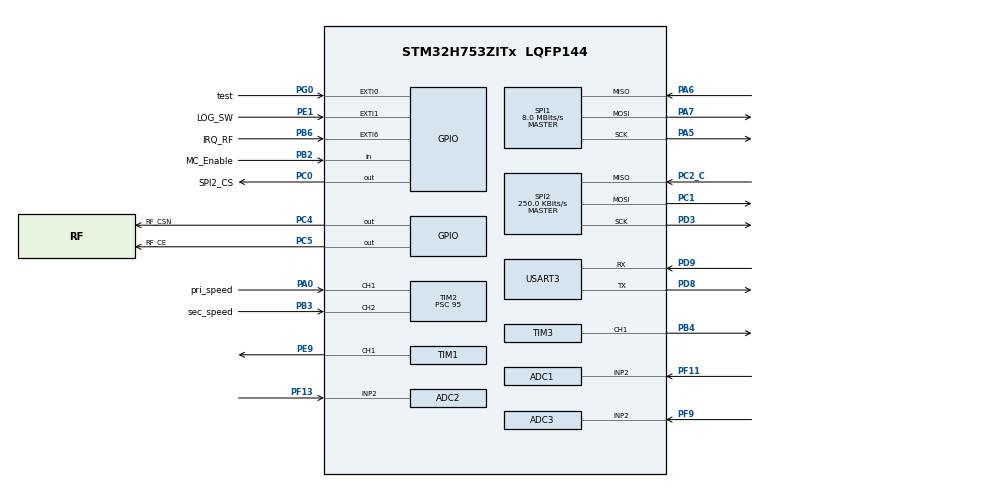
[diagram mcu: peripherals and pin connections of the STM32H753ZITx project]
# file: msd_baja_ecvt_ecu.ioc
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ADC1.Channel-0\#ChannelRegularConversion=ADC_CHANNEL_2
ADC1.ConversionDataManagement=ADC_CONVERSIONDATA_DMA_CIRCULAR
ADC1.ExternalTrigConv=ADC_EXTERNALTRIG_T6_TRGO
ADC1.NbrOfConversionFlag=1
ADC1.OffsetNumber-0\#ChannelRegularConversion=ADC_OFFSET_NONE
ADC1.OffsetSignedSaturation-0\#ChannelRegularConversion=DISABLE
ADC1.Rank-0\#ChannelRegularConversion=1
ADC1.Resolution=ADC_RESOLUTION_12B
ADC1.SamplingTime-0\#ChannelRegularConversion=ADC_SAMPLETIME_1CYCLE_5
ADC1.master=1
ADC2.Channel-0\#ChannelRegularConversion=ADC_CHANNEL_2
ADC2.ConversionDataManagement=ADC_CONVERSIONDATA_DMA_CIRCULAR
ADC2.ExternalTrigConv=ADC_EXTERNALTRIG_T6_TRGO
ADC2.NbrOfConversionFlag=1
ADC2.OffsetNumber-0\#ChannelRegularConversion=ADC_OFFSET_NONE
ADC2.OffsetSignedSaturation-0\#ChannelRegularConversion=DISABLE
ADC2.Rank-0\#ChannelRegularConversion=1
ADC2.Resolution=ADC_RESOLUTION_12B
ADC2.SamplingTime-0\#ChannelRegularConversion=ADC_SAMPLETIME_1CYCLE_5
ADC3.Channel-0\#ChannelRegularConversion=ADC_CHANNEL_2
ADC3.ConversionDataManagement=ADC_CONVERSIONDATA_DMA_CIRCULAR
ADC3.ExternalTrigConv=ADC_EXTERNALTRIG_T6_TRGO
ADC3.NbrOfConversionFlag=1
ADC3.OffsetNumber-0\#ChannelRegularConversion=ADC_OFFSET_NONE
ADC3.OffsetSignedSaturation-0\#ChannelRegularConversion=DISABLE
ADC3.Rank-0\#ChannelRegularConversion=1
ADC3.Resolution=ADC_RESOLUTION_12B
ADC3.SamplingTime-0\#ChannelRegularConversion=ADC_SAMPLETIME_1CYCLE_5
Bdma.ADC3.0.Direction=DMA_PERIPH_TO_MEMORY
Bdma.ADC3.0.EventEnable=DISABLE
Bdma.ADC3.0.Instance=BDMA_Channel0
Bdma.ADC3.0.MemDataAlignment=DMA_MDATAALIGN_HALFWORD
Bdma.ADC3.0.MemInc=DMA_MINC_ENABLE
Bdma.ADC3.0.Mode=DMA_CIRCULAR
Bdma.ADC3.0.PeriphDataAlignment=DMA_PDATAALIGN_HALFWORD
Bdma.ADC3.0.PeriphInc=DMA_PINC_DISABLE
Bdma.ADC3.0.Polarity=HAL_DMAMUX_REQ_GEN_RISING
Bdma.ADC3.0.Priority=DMA_PRIORITY_LOW
Bdma.ADC3.0.RequestNumber=1
Bdma.ADC3.0.SignalID=NONE
Bdma.ADC3.0.SyncEnable=DISABLE
Bdma.ADC3.0.SyncPolarity=HAL_DMAMUX_SYNC_NO_EVENT
Bdma.ADC3.0.SyncRequestNumber=1
Bdma.ADC3.0.SyncSignalID=NONE
Bdma.Request0=ADC3
Bdma.RequestsNb=1
CORTEX_M7.CPU_DCache=Disabled
CORTEX_M7.CPU_ICache=Disabled
CORTEX_M7.MPU_Control=__NULL
CORTEX_M7.default_mode_Activation=1
Dma.ADC1.0.Direction=DMA_PERIPH_TO_MEMORY
Dma.ADC1.0.EventEnable=DISABLE
Dma.ADC1.0.FIFOMode=DMA_FIFOMODE_DISABLE
Dma.ADC1.0.Instance=DMA1_Stream0
Dma.ADC1.0.MemDataAlignment=DMA_MDATAALIGN_HALFWORD
Dma.ADC1.0.MemInc=DMA_MINC_ENABLE
Dma.ADC1.0.Mode=DMA_CIRCULAR
Dma.ADC1.0.PeriphDataAlignment=DMA_PDATAALIGN_HALFWORD
Dma.ADC1.0.PeriphInc=DMA_PINC_DISABLE
Dma.ADC1.0.Polarity=HAL_DMAMUX_REQ_GEN_RISING
Dma.ADC1.0.Priority=DMA_PRIORITY_LOW
Dma.ADC1.0.RequestNumber=1
Dma.ADC1.0.SignalID=NONE
Dma.ADC1.0.SyncEnable=DISABLE
Dma.ADC1.0.SyncPolarity=HAL_DMAMUX_SYNC_NO_EVENT
Dma.ADC1.0.SyncRequestNumber=1
Dma.ADC1.0.SyncSignalID=NONE
Dma.ADC2.1.Direction=DMA_PERIPH_TO_MEMORY
Dma.ADC2.1.EventEnable=DISABLE
Dma.ADC2.1.FIFOMode=DMA_FIFOMODE_DISABLE
Dma.ADC2.1.Instance=DMA1_Stream1
Dma.ADC2.1.MemDataAlignment=DMA_MDATAALIGN_HALFWORD
Dma.ADC2.1.MemInc=DMA_MINC_ENABLE
Dma.ADC2.1.Mode=DMA_CIRCULAR
Dma.ADC2.1.PeriphDataAlignment=DMA_PDATAALIGN_HALFWORD
Dma.ADC2.1.PeriphInc=DMA_PINC_DISABLE
Dma.ADC2.1.Polarity=HAL_DMAMUX_REQ_GEN_RISING
Dma.ADC2.1.Priority=DMA_PRIORITY_LOW
Dma.ADC2.1.RequestNumber=1
Dma.ADC2.1.SignalID=NONE
Dma.ADC2.1.SyncEnable=DISABLE
Dma.ADC2.1.SyncPolarity=HAL_DMAMUX_SYNC_NO_EVENT
Dma.ADC2.1.SyncRequestNumber=1
Dma.ADC2.1.SyncSignalID=NONE
Dma.Request0=ADC1
Dma.Request1=ADC2
Dma.Request2=TIM2_CH2
Dma.Request3=TIM2_CH1
Dma.TIM2_CH1.3.Direction=DMA_PERIPH_TO_MEMORY
Dma.TIM2_CH1.3.EventEnable=DISABLE
Dma.TIM2_CH1.3.FIFOMode=DMA_FIFOMODE_DISABLE
Dma.TIM2_CH1.3.Instance=DMA1_Stream2
Dma.TIM2_CH1.3.MemDataAlignment=DMA_MDATAALIGN_WORD
Dma.TIM2_CH1.3.MemInc=DMA_MINC_ENABLE
Dma.TIM2_CH1.3.Mode=DMA_CIRCULAR
Dma.TIM2_CH1.3.PeriphDataAlignment=DMA_PDATAALIGN_WORD
Dma.TIM2_CH1.3.PeriphInc=DMA_PINC_DISABLE
Dma.TIM2_CH1.3.Polarity=HAL_DMAMUX_REQ_GEN_RISING
Dma.TIM2_CH1.3.Priority=DMA_PRIORITY_LOW
Dma.TIM2_CH1.3.RequestNumber=1
Dma.TIM2_CH1.3.SignalID=NONE
Dma.TIM2_CH1.3.SyncEnable=DISABLE
Dma.TIM2_CH1.3.SyncPolarity=HAL_DMAMUX_SYNC_NO_EVENT
Dma.TIM2_CH1.3.SyncRequestNumber=1
Dma.TIM2_CH1.3.SyncSignalID=NONE
Dma.TIM2_CH2.2.Direction=DMA_PERIPH_TO_MEMORY
Dma.TIM2_CH2.2.EventEnable=DISABLE
Dma.TIM2_CH2.2.FIFOMode=DMA_FIFOMODE_DISABLE
Dma.TIM2_CH2.2.Instance=DMA1_Stream3
Dma.TIM2_CH2.2.MemDataAlignment=DMA_MDATAALIGN_WORD
Dma.TIM2_CH2.2.MemInc=DMA_MINC_ENABLE
Dma.TIM2_CH2.2.Mode=DMA_CIRCULAR
Dma.TIM2_CH2.2.PeriphDataAlignment=DMA_PDATAALIGN_WORD
Dma.TIM2_CH2.2.PeriphInc=DMA_PINC_DISABLE
Dma.TIM2_CH2.2.Polarity=HAL_DMAMUX_REQ_GEN_RISING
Dma.TIM2_CH2.2.Priority=DMA_PRIORITY_LOW
Dma.TIM2_CH2.2.RequestNumber=1
Dma.TIM2_CH2.2.SignalID=NONE
Dma.TIM2_CH2.2.SyncEnable=DISABLE
Dma.TIM2_CH2.2.SyncPolarity=HAL_DMAMUX_SYNC_NO_EVENT
Dma.TIM2_CH2.2.SyncRequestNumber=1
Dma.TIM2_CH2.2.SyncSignalID=NONE
FREERTOS.Queues01=helix_angle_queue,16,float,0,Dynamic,NULL,NULL;throttle_angle_queue,16,float,0,Dynamic,NULL,NULL;pri_rpm_queue,16,float,0,Dynamic,NULL,NULL;sec_rpm_queue,16,float,0,Dynamic,NULL,NULL;pidconfig_queue,4,PIDConfig,0,Dynamic,NULL,NULL;RFCommandQueue,16,16,1,Dynamic,NULL,NULL;sensor_data_mc_q,4,sensor_data_t,0,Dynamic,NULL,NULL;sensor_data_debug_q,4,sensor_data_t,0,Dynamic,NULL,NULL;sensor_data_log_q,60,sensor_data_t,0,Dynamic,NULL,NULL
FREERTOS.Tasks01=defaultTask,24,128,StartDefaultTask,Default,NULL,Dynamic,NULL,NULL;Sensor_Reading,38,1028,Start_Sensor_Reading,Default,NULL,Dynamic,NULL,NULL;Motor_Control,39,1028,Start_Motor_Control,Default,NULL,Dynamic,NULL,NULL;Debug_Disp,8,256,Start_Debug_Disp,Default,NULL,Dynamic,NULL,NULL;ReceiveRF,29,512,receiveRFCommand,Default,NULL,Dynamic,NULL,NULL;processRF,20,1028,processRFCommand,Default,NULL,Dynamic,NULL,NULL;loggingTask,27,512,logData,Default,NULL,Dynamic,NULL,NULL
FREERTOS.configTOTAL_HEAP_SIZE=28000
FREERTOS.configUSE_NEWLIB_REENTRANT=1
Mcu.Family=STM32H7
Mcu.Name=STM32H753ZITx
Mcu.Package=LQFP144
NUCLEO-H753ZI.BUTTON=1
NUCLEO-H753ZI.LD1=true
NUCLEO-H753ZI.LD2=true
NUCLEO-H753ZI.LD3=true
NUCLEO-H753ZI.VCP=false
NVIC.BDMA_Channel0_IRQn=true\:5\:0\:false\:false\:true\:true\:false\:true\:true
NVIC.DMA1_Stream0_IRQn=true\:5\:0\:false\:false\:true\:true\:false\:true\:true
NVIC.DMA1_Stream1_IRQn=true\:5\:0\:false\:false\:true\:true\:false\:true\:true
NVIC.DMA1_Stream2_IRQn=true\:5\:0\:false\:false\:true\:true\:false\:true\:true
NVIC.DMA1_Stream3_IRQn=true\:5\:0\:false\:false\:true\:true\:false\:true\:true
NVIC.EXTI0_IRQn=true\:5\:0\:false\:false\:true\:true\:true\:true\:true
NVIC.EXTI15_10_IRQn=true\:5\:0\:false\:false\:true\:true\:false\:true\:true
NVIC.EXTI1_IRQn=true\:5\:0\:false\:false\:true\:true\:true\:true\:true
NVIC.EXTI9_5_IRQn=true\:5\:0\:false\:false\:true\:true\:true\:true\:true
NVIC.PriorityGroup=NVIC_PRIORITYGROUP_4
NVIC.SPI1_IRQn=true\:5\:0\:false\:false\:true\:true\:true\:true\:true
NVIC.TIM17_IRQn=true\:15\:0\:false\:false\:true\:false\:false\:true\:true
NVIC.TimeBase=TIM17_IRQn
NVIC.TimeBaseIP=TIM17
NVIC.USART3_IRQn=true\:5\:0\:false\:false\:true\:true\:true\:true\:true
PA0.GPIO_Label=pri_speed
PA0.GPIO_ModeDefaultPP=GPIO_MODE_AF_OD
PA0.GPIO_PuPd=GPIO_NOPULL
PA0.GPIO_Speed=GPIO_SPEED_FREQ_VERY_HIGH
PA0.Signal=S_TIM2_CH1_ETR
PA5.Mode=Full_Duplex_Master
PA5.Signal=SPI1_SCK
PA6.Mode=Full_Duplex_Master
PA6.Signal=SPI1_MISO
PA7.Mode=Full_Duplex_Master
PA7.Signal=SPI1_MOSI
PB2.GPIO_Label=MC_Enable
PB2.GPIO_PuPd=GPIO_PULLUP
PB2.Signal=GPIO_Input
PB3\ (JTDO/TRACESWO).GPIO_Label=sec_speed
PB3\ (JTDO/TRACESWO).GPIO_ModeDefaultPP=GPIO_MODE_AF_OD
PB3\ (JTDO/TRACESWO).GPIO_PuPd=GPIO_NOPULL
PB3\ (JTDO/TRACESWO).GPIO_Speed=GPIO_SPEED_FREQ_VERY_HIGH
PB3\ (JTDO/TRACESWO).Signal=S_TIM2_CH2
PB4\ (NJTRST).Signal=S_TIM3_CH1
PB6.GPIO_Label=IRQ_RF
PB6.GPIO_ModeDefaultEXTI=GPIO_MODE_IT_FALLING
PB6.GPIO_PuPd=GPIO_PULLUP
PB6.Signal=GPXTI6
PC0.GPIO_Label=SPI2_CS
PC0.GPIO_PuPd=GPIO_PULLUP
PC0.GPIO_Speed=GPIO_SPEED_FREQ_MEDIUM
PC0.PinState=GPIO_PIN_SET
PC0.Signal=GPIO_Output
PC1.GPIO_PuPd=GPIO_NOPULL
PC1.GPIO_Speed=GPIO_SPEED_FREQ_VERY_HIGH
PC1.Mode=Full_Duplex_Master
PC1.Signal=SPI2_MOSI
PC14-OSC32_IN\ (OSC32_IN).Signal=RCC_OSC32_IN
PC15-OSC32_OUT\ (OSC32_OUT).Signal=RCC_OSC32_OUT
PC2_C.GPIO_PuPd=GPIO_PULLUP
PC2_C.GPIO_Speed=GPIO_SPEED_FREQ_VERY_HIGH
PC2_C.Mode=Full_Duplex_Master
PC2_C.Signal=SPI2_MISO
PC4.GPIO_Label=RF_CSN
PC4.GPIO_Speed=GPIO_SPEED_FREQ_HIGH
PC4.Signal=GPIO_Output
PC5.GPIO_Label=RF_CE
PC5.GPIO_Speed=GPIO_SPEED_FREQ_HIGH
PC5.Signal=GPIO_Output
PD3.GPIO_PuPd=GPIO_NOPULL
PD3.GPIO_Speed=GPIO_SPEED_FREQ_VERY_HIGH
PD3.Mode=Full_Duplex_Master
PD3.Signal=SPI2_SCK
PD8.Mode=Asynchronous
PD8.Signal=USART3_TX
PD9.Mode=Asynchronous
PD9.Signal=USART3_RX
PE1.GPIO_Label=LOG_SW
PE1.GPIO_ModeDefaultEXTI=GPIO_MODE_IT_RISING_FALLING
PE1.GPIO_PuPd=GPIO_PULLUP
PE1.Signal=GPXTI1
PE9.Signal=S_TIM1_CH1
PF11.Mode=IN2-Single-Ended
PF11.Signal=ADC1_INP2
PF13.Mode=IN2-Single-Ended
PF13.Signal=ADC2_INP2
PF9.Mode=IN2-Single-Ended
PF9.Signal=ADC3_INP2
PG0.GPIO_Label=test
PG0.GPIO_PuPd=GPIO_PULLUP
PG0.Signal=GPXTI0
PH0-OSC_IN\ (PH0).Signal=RCC_OSC_IN
PH1-OSC_OUT\ (PH1).Signal=RCC_OSC_OUT
ProjectManager.HeapSize=0x200
ProjectManager.StackSize=0x400
ProjectManager.TargetToolchain=STM32CubeIDE
RCC.ADCFreq_Value=80000000
RCC.APB1Freq_Value=48000000
RCC.APB2Freq_Value=96000000
RCC.APB3Freq_Value=96000000
RCC.APB4Freq_Value=96000000
RCC.CortexFreq_Value=96000000
RCC.D2PPRE1=RCC_APB1_DIV2
RCC.DIVM1=4
RCC.DIVM2=4
RCC.DIVN1=12
RCC.DIVN2=10
RCC.DIVQ1=3
RCC.HCLKFreq_Value=96000000
RCC.HSE_VALUE=8000000
RCC.PLL2FRACN=0
RCC.PLL3FRACN=0
RCC.PLLFRACN=0
RCC.PWR_Regulator_Voltage_Scale=PWR_REGULATOR_VOLTAGE_SCALE2
RCC.SYSCLKFreq_VALUE=96000000
RCC.SYSCLKSource=RCC_SYSCLKSOURCE_PLLCLK
RCC.USBFreq_Value=64000000
SH.S_TIM1_CH1.0=TIM1_CH1,PWM Generation1 CH1
SH.S_TIM2_CH1_ETR.0=TIM2_CH1,Input_Capture1_from_TI1
SH.S_TIM2_CH2.0=TIM2_CH2,Input_Capture2_from_TI2
SH.S_TIM3_CH1.0=TIM3_CH1,PWM Generation1 CH1
SPI1.BaudRatePrescaler=SPI_BAUDRATEPRESCALER_8
SPI1.CalculateBaudRate=8.0 MBits/s
SPI1.DataSize=SPI_DATASIZE_8BIT
SPI1.Direction=SPI_DIRECTION_2LINES
SPI1.Mode=SPI_MODE_MASTER
SPI1.VirtualType=VM_MASTER
SPI2.BaudRatePrescaler=SPI_BAUDRATEPRESCALER_256
SPI2.CalculateBaudRate=250.0 KBits/s
SPI2.DataSize=SPI_DATASIZE_8BIT
SPI2.Direction=SPI_DIRECTION_2LINES
SPI2.Mode=SPI_MODE_MASTER
SPI2.VirtualType=VM_MASTER
TIM1.Channel-PWM\ Generation1\ CH1=TIM_CHANNEL_1
TIM1.ClockDivision=TIM_CLOCKDIVISION_DIV1
TIM1.Period=39999
TIM1.Prescaler=11
TIM2.Channel-Input_Capture1_from_TI1=TIM_CHANNEL_1
TIM2.Channel-Input_Capture2_from_TI2=TIM_CHANNEL_2
TIM2.ICPolarity_CH2=TIM_INPUTCHANNELPOLARITY_FALLING
TIM2.Prescaler=95
TIM3.Channel-PWM\ Generation1\ CH1=TIM_CHANNEL_1
TIM3.ClockDivision=TIM_CLOCKDIVISION_DIV4
TIM3.Period=39999
TIM3.Prescaler=11
TIM5.Prescaler=95
TIM6.Period=47999
TIM6.Prescaler=2
TIM6.TIM_MasterOutputTrigger=TIM_TRGO_UPDATE
USART3.VirtualMode-Asynchronous=VM_ASYNC
VP_FATFS_VS_Generic.Mode=User_defined
VP_FREERTOS_VS_CMSIS_V2.Mode=CMSIS_V2
VP_MEMORYMAP_VS_MEMORYMAP.Mode=CurAppReg
VP_NUCLEO-H753ZI_VS_BSP_COMMON.Mode=COMMON
VP_SYS_VS_tim17.Mode=TIM17
VP_TIM15_VS_ClockSourceINT.Mode=Internal
VP_TIM5_VS_ClockSourceINT.Mode=Internal
VP_TIM6_VS_ClockSourceINT.Mode=Enable_Timer
board=NUCLEO-H753ZI

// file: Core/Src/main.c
/* USER CODE BEGIN Header */
/**
  ******************************************************************************
  * @file           : main.c
  * @brief          : Main program body
  ******************************************************************************
  * @attention
  *
  * Copyright (c) 2026 STMicroelectronics.
  * All rights reserved.
  *
  * This software is licensed under terms that can be found in the LICENSE file
  * in the root directory of this software component.
  * If no LICENSE file comes with this software, it is provided AS-IS.
  *
  ******************************************************************************
  */
/* USER CODE END Header */
#include "main.h"
#include "cmsis_os.h"
#include "adc.h"
#include "bdma.h"
#include "dma.h"
#include "fatfs.h"
#include "spi.h"
#include "tim.h"
#include "usart.h"
#include "gpio.h"

/* USER CODE BEGIN Includes */
#include <string.h>
#include <stdio.h>
#include <stdlib.h>
#include "Controller_P7.h"
#include "NRF24.h"
#include "NRF24_reg_addresses.h"
/* USER CODE END Includes */

/* USER CODE BEGIN PD */
#define PLD_SIZE 16
#define DEBUG 1
/* USER CODE END PD */

void SystemClock_Config(void);
void PeriphCommonClock_Config(void);
void MX_FREERTOS_Init(void);
/* USER CODE BEGIN PFP */
int _read(int file, char *ptr, int len);
int __io_getchar(void);
// PID Functions
int  INIT_PID              (void);
int CHANGE_PID             (char* code, float value);
void PRINT_PID   		   (void);
// SD Card Functions
int  START_LOG			   (void);
void STOP_LOG			   (void);
int  LOG_DATA_POINT		   (int time, int engine_rpm, int box_rpm);
int  FIND_LOG_LINES		   (void);
// RF Function
int  TRANSMIT_LOG		   (void);
// Timer Functions
void TIM6_SetPeriod_us     (uint32_t us);
//E1
/* USER CODE END PFP */

/* USER CODE BEGIN 0 */
// some variables for FatFs
FATFS FatFs;
FIL fil_PID, fil_LOG; // TODO: Create two log files, one for log and one for PID so they don't interfere
FRESULT fres;
BYTE SDreadBuf[64];
char msg[128];
volatile int log_rate = 100; // Default logging rate in us
// RF Variables
volatile uint8_t nrf_irq_flag = 0;
uint8_t addr_ecvt[5] = {0x20,0x21,0x32,0x43,0x54};
uint8_t addr_gui[5]  = {0x10,0x21,0x32,0x43,0x54};
char complete_msg[10] = "COMPLETE";
typedef struct __attribute__((packed)) {
    uint32_t time;
    uint16_t engine_rpm;
    uint16_t box_rpm;
} CompactLogEntry;
// LOG variables
volatile bool isLogging = 0;
volatile uint8_t logSwitchflg = 0;
volatile uint8_t record_log_flag = 0;
volatile uint8_t uart_command_flag = 0;
char line_buffer[64];
uint8_t rx_uart3_buffer[64];
int rx_uart3_index = 0;
int log_index = 0;
uint8_t rx_byte;

/* USER CODE END 0 */

int main(void)
{

  /* MCU Configuration--------------------------------------------------------*/

  /* Reset of all peripherals, Initializes the Flash interface and the Systick. */
  HAL_Init();

  /* Configure the system clock */
  SystemClock_Config();

  /* Configure the peripherals common clocks */
  PeriphCommonClock_Config();

  /* USER CODE BEGIN SysInit */
  HAL_SYSCFG_AnalogSwitchConfig(SYSCFG_SWITCH_PC2, SYSCFG_SWITCH_PC2_CLOSE);

  /* USER CODE END SysInit */

  /* Initialize all configured peripherals */
  MX_GPIO_Init();
  MX_DMA_Init();
  MX_BDMA_Init();
  MX_ADC1_Init();
  MX_TIM6_Init();
  MX_ADC2_Init();
  MX_TIM2_Init();
  MX_TIM3_Init();
  MX_TIM1_Init();
  MX_SPI1_Init();
  MX_FATFS_Init();
  MX_ADC3_Init();
  MX_TIM5_Init();
  MX_TIM15_Init();
  MX_SPI2_Init();
  MX_USART3_UART_Init();
  /* USER CODE BEGIN 2 */
  printf("\x1B[?25l\x1B[2J\x1B[H");

  // NRF24 init
  csn_high();
  nrf24_init();
  nrf24_tx_pwr(_0dbm);
  nrf24_data_rate(_2mbps);
  nrf24_set_channel(7);
  nrf24_set_crc(en_crc, _1byte);
  nrf24_pipe_pld_size(0, PLD_SIZE);
  nrf24_auto_ack_all(enable);     // Enable ACKs for all pipes
  nrf24_auto_retr_delay(5);       // Set delay (5 = 1500us). Critical for reliable ACKs.
  nrf24_auto_retr_limit(15);      // Try up to 15 times before giving up
  nrf24_mode_rx(addr_ecvt);

  HAL_UART_Receive_IT(&huart3, &rx_byte, 1);
  HAL_TIM_Base_Start(&htim5);
  /* USER CODE END 2 */

  /* Init scheduler */
  osKernelInitialize();  /* Call init function for freertos objects (in cmsis_os2.c) */
  MX_FREERTOS_Init();

  /* Initialize leds */
  BSP_LED_Init(LED_GREEN);
  BSP_LED_Init(LED_BLUE);
  BSP_LED_Init(LED_RED);

  /* Initialize USER push-button, will be used to trigger an interrupt each time it's pressed.*/
  BSP_PB_Init(BUTTON_USER, BUTTON_MODE_EXTI);

  /* Start scheduler */
  osKernelStart();

  /* We should never get here as control is now taken by the scheduler */

  /* Infinite loop */
  while (1)
  {

  }
}

void SystemClock_Config(void)
{
  RCC_OscInitTypeDef RCC_OscInitStruct = {0};
  RCC_ClkInitTypeDef RCC_ClkInitStruct = {0};

  /** Supply configuration update enable
  */
  HAL_PWREx_ConfigSupply(PWR_LDO_SUPPLY);

  /** Configure the main internal regulator output voltage
  */
  __HAL_PWR_VOLTAGESCALING_CONFIG(PWR_REGULATOR_VOLTAGE_SCALE2);

  while(!__HAL_PWR_GET_FLAG(PWR_FLAG_VOSRDY)) {}

  /** Initializes the RCC Oscillators according to the specified parameters
  * in the RCC_OscInitTypeDef structure.
  */
  RCC_OscInitStruct.OscillatorType = RCC_OSCILLATORTYPE_HSI;
  RCC_OscInitStruct.HSIState = RCC_HSI_DIV1;
  RCC_OscInitStruct.HSICalibrationValue = RCC_HSICALIBRATION_DEFAULT;
  RCC_OscInitStruct.PLL.PLLState = RCC_PLL_ON;
  RCC_OscInitStruct.PLL.PLLSource = RCC_PLLSOURCE_HSI;
  RCC_OscInitStruct.PLL.PLLM = 4;
  RCC_OscInitStruct.PLL.PLLN = 12;
  RCC_OscInitStruct.PLL.PLLP = 2;
  RCC_OscInitStruct.PLL.PLLQ = 3;
  RCC_OscInitStruct.PLL.PLLR = 2;
  RCC_OscInitStruct.PLL.PLLRGE = RCC_PLL1VCIRANGE_3;
  RCC_OscInitStruct.PLL.PLLVCOSEL = RCC_PLL1VCOWIDE;
  RCC_OscInitStruct.PLL.PLLFRACN = 0;
  if (HAL_RCC_OscConfig(&RCC_OscInitStruct) != HAL_OK)
  {
    Error_Handler();
  }

  /** Initializes the CPU, AHB and APB buses clocks
  */
  RCC_ClkInitStruct.ClockType = RCC_CLOCKTYPE_HCLK|RCC_CLOCKTYPE_SYSCLK
                              |RCC_CLOCKTYPE_PCLK1|RCC_CLOCKTYPE_PCLK2
                              |RCC_CLOCKTYPE_D3PCLK1|RCC_CLOCKTYPE_D1PCLK1;
  RCC_ClkInitStruct.SYSCLKSource = RCC_SYSCLKSOURCE_PLLCLK;
  RCC_ClkInitStruct.SYSCLKDivider = RCC_SYSCLK_DIV1;
  RCC_ClkInitStruct.AHBCLKDivider = RCC_HCLK_DIV1;
  RCC_ClkInitStruct.APB3CLKDivider = RCC_APB3_DIV1;
  RCC_ClkInitStruct.APB1CLKDivider = RCC_APB1_DIV2;
  RCC_ClkInitStruct.APB2CLKDivider = RCC_APB2_DIV1;
  RCC_ClkInitStruct.APB4CLKDivider = RCC_APB4_DIV1;

  if (HAL_RCC_ClockConfig(&RCC_ClkInitStruct, FLASH_LATENCY_1) != HAL_OK)
  {
    Error_Handler();
  }
}

void PeriphCommonClock_Config(void)
{
  RCC_PeriphCLKInitTypeDef PeriphClkInitStruct = {0};

  /** Initializes the peripherals clock
  */
  PeriphClkInitStruct.PeriphClockSelection = RCC_PERIPHCLK_ADC;
  PeriphClkInitStruct.PLL2.PLL2M = 4;
  PeriphClkInitStruct.PLL2.PLL2N = 10;
  PeriphClkInitStruct.PLL2.PLL2P = 2;
  PeriphClkInitStruct.PLL2.PLL2Q = 2;
  PeriphClkInitStruct.PLL2.PLL2R = 2;
  PeriphClkInitStruct.PLL2.PLL2RGE = RCC_PLL2VCIRANGE_3;
  PeriphClkInitStruct.PLL2.PLL2VCOSEL = RCC_PLL2VCOMEDIUM;
  PeriphClkInitStruct.PLL2.PLL2FRACN = 0;
  PeriphClkInitStruct.AdcClockSelection = RCC_ADCCLKSOURCE_PLL2;
  if (HAL_RCCEx_PeriphCLKConfig(&PeriphClkInitStruct) != HAL_OK)
  {
    Error_Handler();
  }
}

/* USER CODE BEGIN 4 */
int _read(int file, char *ptr, int len)
{
    //HAL_UART_Receive(&hcom_uart[COM1], (uint8_t *)ptr, 1, HAL_MAX_DELAY);
    return 1;
}

int __io_getchar(void)
{
    uint8_t ch;
    //HAL_UART_Receive(&hcom_uart[COM1], &ch, 1, HAL_MAX_DELAY);
    return ch;
}

void HAL_GPIO_EXTI_Callback(uint16_t GPIO_Pin)
{
    if(GPIO_Pin == IRQ_RF_Pin)
    {
        nrf_irq_flag = 1;
    }

    if(GPIO_Pin == LOG_SW_Pin){
    	logSwitchflg = 1;
    }
}

void HAL_UART_RxCpltCallback(UART_HandleTypeDef *huart)
{
    if (huart->Instance == USART3)
    {
        // 1. DO SOMETHING with the data (e.g., save it to a buffer)
    	rx_uart3_buffer[rx_uart3_index++] = rx_byte;

    	if(rx_byte == '\n' || rx_byte == '\r'){
    		uart_command_flag = 1;
    		rx_uart3_index = 0;
    	}
        // 2. RE-ENABLE the interrupt
        HAL_UART_Receive_IT(&huart3, &rx_byte, 1);
    }
}

void HAL_UART_ErrorCallback(UART_HandleTypeDef *huart)
{
    if (huart->Instance == USART3)
    {
    	// Force the UART state back to "Ready"
    	huart3.RxState = HAL_UART_STATE_READY;
    	huart3.Lock = HAL_UNLOCKED;

    	// Clear all hardware error flags
    	__HAL_UART_CLEAR_OREFLAG(&huart3);

    	// Try to start again
    	HAL_UART_Receive_IT(&huart3, &rx_byte, 1);
    }
}

// Reads the PID.txt saved PID values and assigns them to the PID data structure (Controller_P7_P)
// Returns 0 if the file was unable to be opened and 1 if the PID value assignments were successful
int INIT_PID(){
	int temp_int;
	float temp_float;
	fres = f_mount(&FatFs, "", 1);
    if (fres != FR_OK) {
	  return 0;
    }

	// Open file
	fres = f_open(&fil_PID, "PID.txt", FA_READ);
    if (fres != FR_OK) {
    	return 0;
    }

	// 1. Read Log Rate (Line 1)
	if (f_gets((TCHAR*)SDreadBuf, sizeof(SDreadBuf), &fil_PID)) {
		// "Log Rate %lf" skips the text and reads the double
		sscanf((TCHAR*)SDreadBuf, "Log Rate %d", &log_rate);
	} else {
		return 0;
	}

	// 2. Read the 4 PID sets (4 lines each)
	for (int i = 0; i < 16; i++) {
	    // Read P line
	    if (f_gets((TCHAR*)SDreadBuf, sizeof(SDreadBuf), &fil_PID)) {
	        if(i == 3 || i == 11){ // All values except RPM Low and High set points are floats
	        	sscanf((TCHAR*)SDreadBuf, " %*s %d", &temp_int);
	        } else{
	        	sscanf((TCHAR*)SDreadBuf, " %*s %f", &temp_float);
	        }
	        // Set correct variable in control scheme

	        switch(i){
				case 0: // P1
					Controller_P7_P.Prop_RPM_Low = temp_float;
					break;
				case 1: // I1
					Controller_P7_P.Int_RPM_Low = temp_float;
					break;
				case 2: // D1
					Controller_P7_P.Der_RPM_Low = temp_float;
					break;
				case 3: // Low RPM SP
					Controller_P7_P.Omega_Low = temp_int;
					break;
				case 4: // P2
					Controller_P7_P.Prop_GR_Low = temp_float;
					break;
				case 5: // I2
					Controller_P7_P.Int_GR_Low = temp_float;
					break;
				case 6: // D2
					Controller_P7_P.Der_GR_Low = temp_float;
					break;
				case 7: // Low Gear SP
					Controller_P7_P.Phi_max = temp_float;
					break;
				case 8: // P3
					Controller_P7_P.Prop_RPM_High = temp_float;
					break;
				case 9: // I3
					Controller_P7_P.Int_RPM_High = temp_float;
					break;
				case 10: // D3
					Controller_P7_P.Der_RPM_High = temp_float;
					break;
				case 11: // High RPM SP
					Controller_P7_P.Omega_High = temp_int;
					break;
				case 12: // P4
					Controller_P7_P.Prop_GR_High = temp_float;
					break;
				case 13: // I4
					Controller_P7_P.Int_GR_High = temp_float;
					break;
				case 14: // D4
					Controller_P7_P.Der_GR_High = temp_float;
					break;
				case 15: // High Gear SP
					Controller_P7_P.Phi_min = temp_float;
					break;
	        }
	    } else {
	       return 0;
	    }
	}

    // Close file
    f_close(&fil_PID);

    // De-mount drive
//    f_mount(NULL, "", 0);

    return 1;

}

// Changes the PID values in the PID structure and overwrites the value in PID.txt
// Takes in the code in string (Ex. P1, I4, SP2) and the value to change it to
// Returns 0 if the file writing was unsuccessful and 1 if it was successfully written to PID.txt
int CHANGE_PID(char* code, float value){

	if (strncmp(code, "P1", 2) == 0) {
	    Controller_P7_P.Prop_RPM_Low = (real_T) value;
	} else if (strncmp(code, "I1", 2) == 0) {
	    Controller_P7_P.Int_RPM_Low = (real_T) value;
	} else if (strncmp(code, "D1", 2) == 0) {
	    Controller_P7_P.Der_RPM_Low = (real_T) value;
	} else if (strncmp(code, "SP1", 3) == 0) {
	    Controller_P7_P.Omega_Low = (real_T) value;
	} else if (strncmp(code, "P2", 2) == 0) {
	    Controller_P7_P.Prop_GR_Low = (real_T) value;
	} else if (strncmp(code, "I2", 2) == 0) {
	    Controller_P7_P.Int_GR_Low = (real_T) value;
	} else if (strncmp(code, "D2", 2) == 0) {
	    Controller_P7_P.Der_GR_Low = (real_T) value;
	} else if (strncmp(code, "SP2", 3) == 0) {
	    Controller_P7_P.Phi_max = (real_T) value;
	} else if (strncmp(code, "P3", 2) == 0) {
	    Controller_P7_P.Prop_RPM_High = (real_T) value;
	} else if (strncmp(code, "I3", 2) == 0) {
	    Controller_P7_P.Int_RPM_High = (real_T) value;
	} else if (strncmp(code, "D3", 2) == 0) {
	    Controller_P7_P.Der_RPM_High = (real_T) value;
	} else if (strncmp(code, "SP3", 3) == 0) {
	    Controller_P7_P.Omega_High = (real_T) value;
	} else if (strncmp(code, "P4", 2) == 0) {
	    Controller_P7_P.Prop_GR_High = (real_T) value;
	} else if (strncmp(code, "I4", 2) == 0) {
	    Controller_P7_P.Int_GR_High = (real_T) value;
	} else if (strncmp(code, "D4", 2) == 0) {
	    Controller_P7_P.Der_GR_High = (real_T) value;
	} else if (strncmp(code, "SP4", 3) == 0) {
	    Controller_P7_P.Phi_min = (real_T) value;
	} else if (strncmp(code, "LOG", 3) == 0){
		// Do nothing
	} else {
		 return 0;
	}

	// Mount drive
	fres = f_mount(&FatFs, "", 1);
	if (fres != FR_OK) {
	    return 0;
	}

	// Open file
	fres = f_open(&fil_PID, "PID.txt", FA_WRITE | FA_OPEN_ALWAYS | FA_CREATE_ALWAYS);
	if (fres != FR_OK) {
	    return 0;
	}

	char line_buffer[64];

	// Write logging rate
	sprintf(line_buffer, "Log Rate %d\r\n", (int)log_rate);
	f_puts(line_buffer, &fil_PID);
	// P1
	sprintf(line_buffer, "P1 %0.3f\r\n", (double)Controller_P7_P.Prop_RPM_Low);
	f_puts(line_buffer, &fil_PID);
	// I1
	sprintf(line_buffer, "I1 %0.3f\r\n", (double)Controller_P7_P.Int_RPM_Low);
	f_puts(line_buffer, &fil_PID);
	// D1
	sprintf(line_buffer, "D1 %0.3f\r\n", (double)Controller_P7_P.Der_RPM_Low);
	f_puts(line_buffer, &fil_PID);
	// SP1
	sprintf(line_buffer, "SP1 %d\r\n", (int)Controller_P7_P.Omega_Low);
	f_puts(line_buffer, &fil_PID);
	// P2
	sprintf(line_buffer, "P2 %0.3f\r\n", (double)Controller_P7_P.Prop_GR_Low);
	f_puts(line_buffer, &fil_PID);
	// I2
	sprintf(line_buffer, "I2 %0.3f\r\n", (double)Controller_P7_P.Int_GR_Low);
	f_puts(line_buffer, &fil_PID);
	// D2
	sprintf(line_buffer, "D2 %0.3f\r\n", (double)Controller_P7_P.Der_GR_Low);
	f_puts(line_buffer, &fil_PID);
	// SP2
	sprintf(line_buffer, "SP2 %0.3f\r\n", (double)Controller_P7_P.Phi_max);
	f_puts(line_buffer, &fil_PID);
	// P3
	sprintf(line_buffer, "P3 %0.3f\r\n", (double)Controller_P7_P.Prop_RPM_High);
	f_puts(line_buffer, &fil_PID);
	// I3
	sprintf(line_buffer, "I3 %0.3f\r\n", (double)Controller_P7_P.Int_RPM_High);
	f_puts(line_buffer, &fil_PID);
	// D3
	sprintf(line_buffer, "D3 %0.3f\r\n", (double)Controller_P7_P.Der_RPM_High);
	f_puts(line_buffer, &fil_PID);
	// SP3
	sprintf(line_buffer, "SP3 %d\r\n", (int)Controller_P7_P.Omega_High);
	f_puts(line_buffer, &fil_PID);
	// P4
	sprintf(line_buffer, "P4 %0.3f\r\n", (double)Controller_P7_P.Prop_GR_High);
	f_puts(line_buffer, &fil_PID);
	// I4
	sprintf(line_buffer, "I4 %0.3f\r\n", (double)Controller_P7_P.Int_GR_High);
	f_puts(line_buffer, &fil_PID);
	// D4
	sprintf(line_buffer, "D4 %0.3f\r\n", (double)Controller_P7_P.Der_GR_High);
	f_puts(line_buffer, &fil_PID);
	// SP4
	sprintf(line_buffer, "SP4 %0.3f\r\n", (double)Controller_P7_P.Phi_min);
	f_puts(line_buffer, &fil_PID);

	// Close file
	f_close(&fil_PID);
	// De-mount drive
//	f_mount(NULL, "", 0);
	return 1;
}

// Creates "LOG.txt" which overwrites (clears) the previously created log file
// Opens the global file variable
// Returns 1 if successful and 0 if unsuccessful
// Creates "LOG.txt" which overwrites (clears) the previously created log file
// Opens the global file variable
// Returns 1 if successful and 0 if unsuccessful
int START_LOG(){
    FILINFO fno;
    int max_logs = 100;
    char log_file_str[32];

    // Check for what log files exist
    for(int i = 0; i < max_logs; i++){
        snprintf(log_file_str, sizeof(log_file_str), "LOG%d.txt", i);
        fres = f_stat(log_file_str, &fno);
        if(fres == FR_NO_FILE){
            log_index = i;
            break;
        }
        // Maximum log file limit reached
        if(i == max_logs-1){
            return 0;
        }
    }

    // Clear file
    fres = f_open(&fil_LOG, log_file_str, FA_WRITE | FA_OPEN_ALWAYS | FA_CREATE_ALWAYS);
    if (fres != FR_OK) {
        return 0;
    }

    // Log Current PID values at the start of the log
    sprintf(msg, "P1:%.2f I1:%.2f D1:%.2f SP1:%d\r\n",
            (double)Controller_P7_P.Prop_RPM_Low, (double)Controller_P7_P.Int_RPM_Low, (double)Controller_P7_P.Der_RPM_Low, (int)Controller_P7_P.Omega_Low);
    if (f_puts(msg, &fil_LOG) < 0) {
        return 0;
    }
    sprintf(msg, "P2:%.2f I2:%.2f D2:%.2f SP2:%.2f\r\n",
            (double)Controller_P7_P.Prop_GR_Low, (double)Controller_P7_P.Int_GR_Low, (double)Controller_P7_P.Der_GR_Low, (double)Controller_P7_P.Phi_max);
    if (f_puts(msg, &fil_LOG) < 0) {
        return 0;
    }
    sprintf(msg, "P3:%.2f I3:%.2f D3:%.2f SP3:%d\r\n",
            (double)Controller_P7_P.Prop_RPM_High, (double)Controller_P7_P.Int_RPM_High, (double)Controller_P7_P.Der_RPM_High, (int)Controller_P7_P.Omega_High);
    if (f_puts(msg, &fil_LOG) < 0) {
        return 0;
    }
    sprintf(msg, "P4:%.2f I4:%.2f D4:%.2f SP4:%.2f\r\n",
            (double)Controller_P7_P.Prop_GR_High, (double)Controller_P7_P.Int_GR_High, (double)Controller_P7_P.Der_GR_High, (double)Controller_P7_P.Phi_min);
    if (f_puts(msg, &fil_LOG) < 0) {
        return 0;
    }

    return 1;
}

// Closes the global log file (LOG.txt)
void STOP_LOG(){
	// Close file
	f_close(&fil_LOG);
	// De-mount drive
//	f_mount(NULL, "", 0);
}

// Finds the amount of logged data points in LOG.txt (# of lines)
// Returns a positive integer if successful and -1 if not
int FIND_LOG_LINES(){
	int lines_count = 0;

	// Mount drive
	fres = f_mount(&FatFs, "", 1);
	if (fres != FR_OK) {
		return -1;
	}
	// Open file
	fres = f_open(&fil_LOG, "LOG.txt", FA_READ);
	if (fres != FR_OK) {
		return -1;
	}

	while(f_gets((TCHAR*)SDreadBuf, sizeof(SDreadBuf), &fil_LOG)){
		lines_count++;
	}
	if (lines_count > 0) {
	    lines_count++; // account for last line without newline
	}
	// Close file
	f_close(&fil_LOG);
	// De-mount drive
	f_mount(NULL, "", 0);

	return lines_count;
}

void TRANSMIT_LOG_USB(){
    int log_transmitted_index = 0;
    char log_file_str[32];
    char log_line[64];
    // Open log files starting from index 0
    snprintf(log_file_str, sizeof(log_file_str), "LOG%d.txt", log_transmitted_index);

    // While the file LOGx.txt exists
    while(f_open(&fil_LOG, log_file_str, FA_READ) == FR_OK){
        // Indicate to the GUI the start of a log file by printing the log file's name
        printf(log_file_str);
        printf("\r\n");
        // Loop through the log points if the log file exists
        while(f_gets(log_line, sizeof(log_line), &fil_LOG)){
            // Send the log line over USART
            printf(log_line);
        }
        // Move on to the next log file
        log_transmitted_index++;
        snprintf(log_file_str, sizeof(log_file_str), "LOG%d.txt", log_transmitted_index);
    }
    printf("COMPLETE\r\n");
}

// Logs a data point (one line) into LOG.txt (Assumes LOG.txt is open)
// Takes in the data to be logged (time, engine_rpm, and box_rpm)
// Returns 1 if the data point was siccessfully logged and 0 if the f_puts fails
int LOG_DATA_POINT(int time, int engine_rpm, int box_rpm){

    if(f_lseek(&fil_LOG, f_size(&fil_LOG)) != FR_OK){
        return 0;
    }

    // Write logging rate
    sprintf(line_buffer, "%d %d %d\n", time, engine_rpm, box_rpm);
    if (f_puts(line_buffer, &fil_LOG) < 0) {
        return 0;
    }

    return 1;
}

int TRANSMIT_LOG(){
	CompactLogEntry entry;
	if(isLogging){ // Only send when not currently logging
		return 0;
	}
	// Switch to transmit
	nrf24_mode_tx(addr_gui);

	// Get the number of lines in the log file
	int log_lines = FIND_LOG_LINES();
	char log_lines_str[32] = "";
	snprintf(log_lines_str, sizeof(log_lines_str), "%d", log_lines);

	HAL_Delay(100);
	fres = f_mount(&FatFs, "", 1);
	if (fres != FR_OK) {
	  return 0;
	  }
	HAL_Delay(100);
	// Open file
	fres = f_open(&fil_LOG, "LOG.txt", FA_READ);
	if (fres != FR_OK) {
	  return 0;
	}

	// Transmit complete message (Ensure that the NRF24 has switched modes)
	nrf_irq_flag = 0;
	uint8_t result;
	for(int i = 0; i< 50; i++){
	   result = nrf24_transmit_wait((uint8_t*)log_lines_str, strlen(log_lines_str));
	   HAL_Delay(10);
//	   BSP_LED_On(LED_RED);
	   if(result == 0){
//		   BSP_LED_Off(LED_RED);
		   break;
	   }
	}
	nrf_irq_flag = 0;
	char line[64];
	uint8_t status;
	// Begin log file transmission
	if (result == 0) {
		while (f_gets(line, sizeof(line), &fil_LOG)) {
			// Parse text file into our binary struct
			if(sscanf(line, "%lu %hu %hu", &entry.time, &entry.engine_rpm, &entry.box_rpm) >= 3) {
//				BSP_LED_Toggle(LED_RED);
				// Send binary struct
//				while(1){
//					status = nrf24_transmit_wait((uint8_t*)&entry, sizeof(entry));
//					DEBUG_RF();
//					if (status == 0) {
//						break;
//					}
//				}
//
//				if (status != 0) {
//					nrf24_flush_tx(); // Clear the failed packet from buffer
//				}
			}
		}

	} else {
		nrf24_flush_rx();
		// Switch back to receive
		nrf24_mode_rx(addr_ecvt);
		// Close file
		f_close(&fil_LOG);
		// De-mount drive
		f_mount(NULL, "", 0);
		return 0; // Error in intial transmission (Timeout)

	}

	for(int i = 0; i< 50; i++){
		result = nrf24_transmit_wait((uint8_t*)complete_msg, strlen(complete_msg));
		if(result == 0){
			break;
		}
	}

	nrf24_flush_rx();
	// Switch back to receive
	nrf24_mode_rx(addr_ecvt);

	// Close file
	f_close(&fil_LOG);

	// De-mount drive
	f_mount(NULL, "", 0);

	if(result == 0){
		return 1;
	} else {
		return 0;
	}

}

/**
 * @brief  Sets TIM6 interrupt period in microseconds
 * @param  us: Target period in microseconds (e.g., 1000 for 1ms)
 * @retval None
 */
void TIM6_SetPeriod_us(uint32_t us) {
    // 1. Get the PCLK1 frequency
    uint32_t pclk1 = HAL_RCC_GetPCLK1Freq();

    // 2. Determine the actual Timer Clock (H7 doubles it if APB1 divider != 1)
    uint32_t tim_clk;
    if ((RCC->D2CFGR & RCC_D2CFGR_D2PPRE1) == 0) {
        tim_clk = pclk1;
    } else {
        tim_clk = pclk1 * 2;
    }

    // 3. Get the current Prescaler from the register
    uint32_t current_psc = TIM6->PSC + 1;

    // 4. Calculate ARR for microseconds
    // Logic: ARR = (Clock * Seconds) / PSC
    // Since 'us' is microseconds, we divide the denominator by 1,000,000
    uint64_t arr_value = ((uint64_t)tim_clk * us) / (1000000ULL * current_psc);

    // 5. Apply limits for 16-bit Timer
    if (arr_value > 65536) {
        arr_value = 65536;
    } else if (arr_value < 1) {
        arr_value = 1;
    }

    // 6. Update the register
    __HAL_TIM_SET_AUTORELOAD(&htim6, (uint32_t)(arr_value - 1));
}

void PRINT_PID(){
	// 1. Verify Log Rate
	sprintf(msg, "Log Rate Parsed: %d\r\n", log_rate);
	printf(msg);

	// 2. Verify PID Array Values
	sprintf(msg, "P1:%.3f I1:%.3f D1:%.3f SP1:%d\r\n",
			(double)Controller_P7_P.Prop_RPM_Low, (double)Controller_P7_P.Int_RPM_Low, (double)Controller_P7_P.Der_RPM_Low, (int)Controller_P7_P.Omega_Low);
	printf(msg);
	sprintf(msg, "P2:%.3f I2:%.3f D2:%.3f SP2:%.3f\r\n",
			(double)Controller_P7_P.Prop_GR_Low, (double)Controller_P7_P.Int_GR_Low, (double)Controller_P7_P.Der_GR_Low, (double)Controller_P7_P.Phi_max);
	printf(msg);
	sprintf(msg, "P3:%.3f I3:%.3f D3:%.3f SP3:%d\r\n",
			(double)Controller_P7_P.Prop_RPM_High, (double)Controller_P7_P.Int_RPM_High, (double)Controller_P7_P.Der_RPM_High, (int)Controller_P7_P.Omega_High);
	printf(msg);
	sprintf(msg, "P4:%.3f I4:%.3f D4:%.3f SP4:%.3f\r\n",
			(double)Controller_P7_P.Prop_GR_High, (double)Controller_P7_P.Int_GR_High, (double)Controller_P7_P.Der_GR_High, (double)Controller_P7_P.Phi_min);
	printf(msg);
}
/* USER CODE END 4 */

void HAL_TIM_PeriodElapsedCallback(TIM_HandleTypeDef *htim)
{
  if (htim->Instance == TIM17)
  {
    HAL_IncTick();
  }
  /* USER CODE BEGIN Callback 1 */
  if (htim->Instance == TIM6)
  {
//	  if (isLogging)
//	  {
		record_log_flag = 1;
//	  }
  }
  /* USER CODE END Callback 1 */
}

void Error_Handler(void)
{
  __disable_irq();
  while (1)
  {
  }
}

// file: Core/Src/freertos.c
/* USER CODE BEGIN Header */
/**
  ******************************************************************************
  * File Name          : freertos.c
  * Description        : Code for freertos applications
  ******************************************************************************
  * @attention
  *
  * Copyright (c) 2026 STMicroelectronics.
  * All rights reserved.
  *
  * This software is licensed under terms that can be found in the LICENSE file
  * in the root directory of this software component.
  * If no LICENSE file comes with this software, it is provided AS-IS.
  *
  ******************************************************************************
  */
/* USER CODE END Header */

#include "FreeRTOS.h"
#include "task.h"
#include "main.h"
#include "cmsis_os.h"

/* USER CODE BEGIN Includes */
#include "print_debug.h"
#include <stdio.h>
#include <stddef.h>
#include "adc.h"
#include "tim.h"
#include "motor_control.h"
#include "sensor_filter.h"
#include "Controller_P7.h"
#include "sensor_conversion.h"
#include "main.h"
#include "NRF24.h"
#include "NRF24_reg_addresses.h"

/* USER CODE END Includes */

/* USER CODE BEGIN PD */
#define HELIX_ANGLE_BUF_LEN 1
#define THROTTLE_ANGLE_BUF_LEN 1
#define MOTOR_CURR_BUF_LEN 1
#define PRIM_RPM_BUF_LEN 2
#define SEC_RPM_BUF_LEN 2

#define NEUTRAL 11999
#define MAX_FORWARD	15999
#define MAX_REVERSE 7999
#define PWM_RANGE 8000

#define MOTOR_CONTROL 2

#define PLD_SIZE 16

#define DEBUG 1

/* USER CODE END PD */

/* USER CODE BEGIN Variables */
uint16_t helix_angle_buf[HELIX_ANGLE_BUF_LEN];
uint16_t throttle_angle_buf[THROTTLE_ANGLE_BUF_LEN];

uint16_t motor_curr_buf[MOTOR_CURR_BUF_LEN] __attribute__((section(".sram4_section")));
uint32_t prim_rpm_buf[PRIM_RPM_BUF_LEN];
uint32_t sec_rpm_buf[SEC_RPM_BUF_LEN];

//  uint16_t speed = NEUTRAL_SPEED;
//  uint16_t curr_position = 0;
//  uint16_t pos_setpoint = 0;
//  uint16_t helix_angle = 0;
extern DMA_HandleTypeDef hdma_tim2_ch1;
extern DMA_HandleTypeDef hdma_tim2_ch2;

// RF Variables
extern uint8_t nrf_irq_flag;
extern int log_rate;
uint8_t data_Rx[PLD_SIZE*5];

// LOG Variables
extern uint8_t record_log_flag;
extern bool isLogging;
extern uint8_t logSwitchflg;
extern uint8_t uart_command_flag;
extern uint8_t rx_uart3_buffer[64];

extern UART_HandleTypeDef huart3;

#if DEBUG == 1
uint32_t sensor_task_loop_time = 0;
uint32_t mc_task_loop_time = 0;
uint32_t log_task_loop_time = 0;
uint32_t rfrec_task_loop_time = 0;
uint32_t proc_rf_task_loop_time = 0;
#endif
/* USER CODE END Variables */
/* Definitions for defaultTask */
osThreadId_t defaultTaskHandle;
const osThreadAttr_t defaultTask_attributes = {
  .name = "defaultTask",
  .stack_size = 128 * 4,
  .priority = (osPriority_t) osPriorityNormal,
};
/* Definitions for Sensor_Reading */
osThreadId_t Sensor_ReadingHandle;
const osThreadAttr_t Sensor_Reading_attributes = {
  .name = "Sensor_Reading",
  .stack_size = 1028 * 4,
  .priority = (osPriority_t) osPriorityAboveNormal6,
};
/* Definitions for Motor_Control */
osThreadId_t Motor_ControlHandle;
const osThreadAttr_t Motor_Control_attributes = {
  .name = "Motor_Control",
  .stack_size = 1028 * 4,
  .priority = (osPriority_t) osPriorityAboveNormal7,
};
/* Definitions for Debug_Disp */
osThreadId_t Debug_DispHandle;
const osThreadAttr_t Debug_Disp_attributes = {
  .name = "Debug_Disp",
  .stack_size = 256 * 4,
  .priority = (osPriority_t) osPriorityLow,
};
/* Definitions for ReceiveRF */
osThreadId_t ReceiveRFHandle;
const osThreadAttr_t ReceiveRF_attributes = {
  .name = "ReceiveRF",
  .stack_size = 512 * 4,
  .priority = (osPriority_t) osPriorityNormal5,
};
/* Definitions for processRF */
osThreadId_t processRFHandle;
const osThreadAttr_t processRF_attributes = {
  .name = "processRF",
  .stack_size = 1028 * 4,
  .priority = (osPriority_t) osPriorityBelowNormal4,
};
/* Definitions for loggingTask */
osThreadId_t loggingTaskHandle;
const osThreadAttr_t loggingTask_attributes = {
  .name = "loggingTask",
  .stack_size = 512 * 4,
  .priority = (osPriority_t) osPriorityNormal3,
};
/* Definitions for helix_angle_queue */
osMessageQueueId_t helix_angle_queueHandle;
const osMessageQueueAttr_t helix_angle_queue_attributes = {
  .name = "helix_angle_queue"
};
/* Definitions for throttle_angle_queue */
osMessageQueueId_t throttle_angle_queueHandle;
const osMessageQueueAttr_t throttle_angle_queue_attributes = {
  .name = "throttle_angle_queue"
};
/* Definitions for pri_rpm_queue */
osMessageQueueId_t pri_rpm_queueHandle;
const osMessageQueueAttr_t pri_rpm_queue_attributes = {
  .name = "pri_rpm_queue"
};
/* Definitions for sec_rpm_queue */
osMessageQueueId_t sec_rpm_queueHandle;
const osMessageQueueAttr_t sec_rpm_queue_attributes = {
  .name = "sec_rpm_queue"
};
/* Definitions for pidconfig_queue */
osMessageQueueId_t pidconfig_queueHandle;
const osMessageQueueAttr_t pidconfig_queue_attributes = {
  .name = "pidconfig_queue"
};
/* Definitions for RFCommandQueue */
osMessageQueueId_t RFCommandQueueHandle;
const osMessageQueueAttr_t RFCommandQueue_attributes = {
  .name = "RFCommandQueue"
};
/* Definitions for sensor_data_mc_q */
osMessageQueueId_t sensor_data_mc_qHandle;
const osMessageQueueAttr_t sensor_data_mc_q_attributes = {
  .name = "sensor_data_mc_q"
};
/* Definitions for sensor_data_debug_q */
osMessageQueueId_t sensor_data_debug_qHandle;
const osMessageQueueAttr_t sensor_data_debug_q_attributes = {
  .name = "sensor_data_debug_q"
};
/* Definitions for sensor_data_log_q */
osMessageQueueId_t sensor_data_log_qHandle;
const osMessageQueueAttr_t sensor_data_log_q_attributes = {
  .name = "sensor_data_log_q"
};

void StartDefaultTask(void *argument);
void Start_Sensor_Reading(void *argument);
void Start_Motor_Control(void *argument);
void Start_Debug_Disp(void *argument);
void receiveRFCommand(void *argument);
void processRFCommand(void *argument);
void logData(void *argument);

void MX_FREERTOS_Init(void); /* (MISRA C 2004 rule 8.1) */

void MX_FREERTOS_Init(void) {

  /* Create the queue(s) */
  /* creation of helix_angle_queue */
  helix_angle_queueHandle = osMessageQueueNew (16, sizeof(float), &helix_angle_queue_attributes);

  /* creation of throttle_angle_queue */
  throttle_angle_queueHandle = osMessageQueueNew (16, sizeof(float), &throttle_angle_queue_attributes);

  /* creation of pri_rpm_queue */
  pri_rpm_queueHandle = osMessageQueueNew (16, sizeof(float), &pri_rpm_queue_attributes);

  /* creation of sec_rpm_queue */
  sec_rpm_queueHandle = osMessageQueueNew (16, sizeof(float), &sec_rpm_queue_attributes);

  /* creation of pidconfig_queue */
  pidconfig_queueHandle = osMessageQueueNew (4, sizeof(PIDConfig), &pidconfig_queue_attributes);

  /* creation of RFCommandQueue */
  RFCommandQueueHandle = osMessageQueueNew (16, 16, &RFCommandQueue_attributes);

  /* creation of sensor_data_mc_q */
  sensor_data_mc_qHandle = osMessageQueueNew (4, sizeof(sensor_data_t), &sensor_data_mc_q_attributes);

  /* creation of sensor_data_debug_q */
  sensor_data_debug_qHandle = osMessageQueueNew (4, sizeof(sensor_data_t), &sensor_data_debug_q_attributes);

  /* creation of sensor_data_log_q */
  sensor_data_log_qHandle = osMessageQueueNew (60, sizeof(sensor_data_t), &sensor_data_log_q_attributes);

  /* Create the thread(s) */
  /* creation of defaultTask */
  defaultTaskHandle = osThreadNew(StartDefaultTask, NULL, &defaultTask_attributes);

  /* creation of Sensor_Reading */
  Sensor_ReadingHandle = osThreadNew(Start_Sensor_Reading, NULL, &Sensor_Reading_attributes);

  /* creation of Motor_Control */
  Motor_ControlHandle = osThreadNew(Start_Motor_Control, NULL, &Motor_Control_attributes);

  /* creation of Debug_Disp */
  Debug_DispHandle = osThreadNew(Start_Debug_Disp, NULL, &Debug_Disp_attributes);

  /* creation of ReceiveRF */
  ReceiveRFHandle = osThreadNew(receiveRFCommand, NULL, &ReceiveRF_attributes);

  /* creation of processRF */
  processRFHandle = osThreadNew(processRFCommand, NULL, &processRF_attributes);

  /* creation of loggingTask */
  loggingTaskHandle = osThreadNew(logData, NULL, &loggingTask_attributes);

}

void StartDefaultTask(void *argument)
{
  /* USER CODE BEGIN StartDefaultTask */
  /* Infinite loop */
  for(;;)
  {
    osDelay(1000);
  }
  /* USER CODE END StartDefaultTask */
}

/* USER CODE BEGIN Header_Start_Sensor_Reading */
/**
* @brief Function implementing the Sensor_Reading thread.
* 		 This function takes in all sensor values from DMA
* 		 converts it to the required units,
* 		 then sends it to other threads for use
* @param argument: Not used
* @retval None
*/
/* USER CODE END Header_Start_Sensor_Reading */
void Start_Sensor_Reading(void *argument)
{
  /* USER CODE BEGIN Start_Sensor_Reading */
  /* Infinite loop */
	float helix_angle = 0;
	uint8_t helix_angle_prio = 0;
	float throttle_angle = 0;
	uint8_t throttle_angle_prio = 0;
	uint32_t prim_rpm_uint32 = 0;
	uint8_t prim_rpm_prio = 0;
	uint32_t sec_rpm_uint32 = 0;
	uint8_t sec_rpm_prio = 0;
	const uint32_t TIMEOUT = 0;
	SPEED_FIFO prim_speed_fifo = {0};
	uint32_t curr_prim_rpm_tic = 0;
	uint32_t prev_prim_rpm_tic = 0;
	SPEED_FIFO sec_speed_fifo = {0};
	uint32_t curr_sec_rpm_tic = 0;
	uint32_t prev_sec_rpm_tic = 0;
	float prim_rpm = 0.0f;
	float sec_rpm = 0.0f;
	float motor_curr = 0.0f;
	float motor_curr_avg = 0.0f;
	uint8_t prim_rpm_sense_overflow = 0;
	uint8_t sec_rpm_sense_overflow = 0;

	sensor_data_t sensor_data = {0};
	int i = 0;

#if DEBUG == 1
	//Initialize timestep values
	uint32_t prev_sensor_task_tick = __HAL_TIM_GET_COUNTER(&htim5);
	uint32_t curr_sensor_task_tick = prev_sensor_task_tick;
#endif

	//Initialize fifo buffers for speed sensors
	dma_speed_fifo_init(&prim_speed_fifo);
	dma_speed_fifo_init(&sec_speed_fifo);

	//Start ADCs and DMAs for analog sensors
	HAL_ADC_Start_DMA(&hadc1, (uint32_t*)helix_angle_buf, HELIX_ANGLE_BUF_LEN);
	HAL_ADC_Start_DMA(&hadc2, (uint32_t*)throttle_angle_buf, THROTTLE_ANGLE_BUF_LEN);
	HAL_ADC_Start_DMA(&hadc3, (uint32_t*)motor_curr_buf, MOTOR_CURR_BUF_LEN);

	// Start prim and secondary timestep monitors
	HAL_TIM_IC_Start_DMA(&htim2, TIM_CHANNEL_1, prim_speed_fifo.buf, DMA_FIFO_BUF_SIZE);
	HAL_TIM_IC_Start_DMA(&htim2, TIM_CHANNEL_2, sec_speed_fifo.buf, DMA_FIFO_BUF_SIZE);

	// Start sample trigger for ADCs
    HAL_TIM_OC_Start(&htim6, TIM_CHANNEL_1);

  for(;;)
  {

	//Delay time for sensor task (1ms) needed for giving up control to other functions
    osDelay(MC_OS_DELAY);

#if DEBUG == 1
    // Debug only for verifying correct time step of this thread
    curr_sensor_task_tick = __HAL_TIM_GET_COUNTER(&htim5);
	sensor_task_loop_time = curr_sensor_task_tick - prev_sensor_task_tick;
    prev_sensor_task_tick = curr_sensor_task_tick;
#endif

    //Read and convert angles
    sensor_data.helix_angle = adc12b_to_rad(helix_angle_buf[0]);
    sensor_data.throttle_angle = adc12b_to_rad(throttle_angle_buf[0]);

    //Needed for using BDMA
    SCB_InvalidateDCache_by_Addr((uint32_t*)motor_curr_buf, 2);

    motor_curr = adc12b_to_motor_curr(motor_curr_buf[0]);
    sensor_data.motor_curr = moving_average_filter_curr(motor_curr);

    //Read and empty prim rpm fifo so always most recent
    //While data available in either fifo
    while(dma_speed_fifo_available(&prim_speed_fifo, &hdma_tim2_ch1)
    		||dma_speed_fifo_available(&sec_speed_fifo, &hdma_tim2_ch2)){
		//If prim rpm fifo data available
    	if (dma_speed_fifo_available(&prim_speed_fifo, &hdma_tim2_ch1)){
    		//Take current pickup tick value
			curr_prim_rpm_tic = dma_speed_fifo_read_single(&prim_speed_fifo);
			prim_rpm_uint32 = curr_prim_rpm_tic - prev_prim_rpm_tic;
			prev_prim_rpm_tic = curr_prim_rpm_tic;
			prim_rpm = pickup_dt_to_rad_per_sec(prim_rpm_uint32);

		}

		//Read and empty sec rpm fifo so always most recent
		if (dma_speed_fifo_available(&sec_speed_fifo, &hdma_tim2_ch2)){
			curr_sec_rpm_tic = dma_speed_fifo_read_single(&sec_speed_fifo);
			sec_rpm_uint32 = curr_sec_rpm_tic - prev_sec_rpm_tic;
			prev_sec_rpm_tic = curr_sec_rpm_tic;
			sec_rpm = pickup_dt_to_rad_per_sec_gb(sec_rpm_uint32);
		}

	    sensor_data.prim_rpm = prim_rpm;
	    sensor_data.sec_rpm = sec_rpm;

    }

    //Once all sensor data collected, send to motor control
    osMessageQueuePut(sensor_data_mc_qHandle, &sensor_data, 0, 0);
  }
  /* USER CODE END Start_Sensor_Reading */
}

/* USER CODE BEGIN Header_Start_Motor_Control */
uint16_t ccr = NEUTRAL;
sensor_data_t sensor_data_mc = {0};
uint16_t motor_pwm_setpoint = NEUTRAL_SPEED;
float helix_angle_offset_removed = 0.0f;
uint8_t flag_min_pos_safety = 0;
uint8_t flag_max_pos_safety = 0;
uint8_t flag_no_safety = 0;

real_T controller_mode = 0;

/**
* @brief Function implementing the Motor_Control thread.
* @param argument: Not used
* @retval None
*/
/* USER CODE END Header_Start_Motor_Control */
void Start_Motor_Control(void *argument)
{
  /* USER CODE BEGIN Start_Motor_Control */
  /* Infinite loop */
  uint16_t speed = NEUTRAL_SPEED;
//  uint16_t helix_pos = 0;
  uint16_t pos_setpoint = 0;
  uint16_t helix_angle = 0;
  uint8_t helix_angle_prio = 0;
  const uint32_t QUEUE_TIMEOUT= 0;
  uint8_t speed_percent = 0xff;
  uint8_t current_percent = 50;
  char lr_dir = '\0';

  float prim_rpm = 0;
  uint8_t prim_rpm_prio = 0;
  float sec_rpm = 0;
  uint8_t sec_rpm_prio = 0;
  float throttle_pos = 0;
  uint8_t throttle_pos_prio = 0;
  float helix_pos = 0;
  float helix_offset = 2.2;
  sensor_data_t sensor_data_log = {0};

#if DEBUG == 1
  	// DEBUG Tick
	uint32_t prev_mc_task_tick = __HAL_TIM_GET_COUNTER(&htim5);
	uint32_t curr_mc_task_tick = prev_mc_task_tick;
#endif

  PIDConfig mode_pid_sp = {0};
  uint8_t mode_pid_sp_prio = 0;

#if MOTOR_CONTROL == 2
  // Initialize controller variables
  Controller_P7_initialize();

  //Initialize PID values with stored values on SD card
  INIT_PID();
  init_pidconfig(&mode_pid_sp);
#endif
  // Start PWM timer
  __HAL_TIM_SET_COMPARE(&htim1, TIM_CHANNEL_1, NEUTRAL_SPEED);
  HAL_TIM_PWM_Start(&htim1, TIM_CHANNEL_1);

  for(;;)
  {
	  //Delay 1ms
    osDelay(MC_OS_DELAY);

#if DEBUG == 1
    //measure task execution time
    curr_mc_task_tick = __HAL_TIM_GET_COUNTER(&htim5);
    mc_task_loop_time = curr_mc_task_tick - prev_mc_task_tick;
	prev_mc_task_tick = curr_mc_task_tick;
#endif
//    BSP_LED_Toggle(LED_BLUE);
#if MOTOR_CONTROL == 0

    while(osMessageQueueGetCount(helix_pos_mc_queueHandle)){
    	osMessageQueueGet(helix_pos_mc_queueHandle, &helix_pos, &helix_angle_prio, QUEUE_TIMEOUT);
    }
    pos_setpoint = update_setpoint(pos_setpoint, helix_pos);
    speed = pid_loop(pos_setpoint, helix_pos);
    __HAL_TIM_SET_COMPARE(&htim3, TIM_CHANNEL_1, speed);
#elif MOTOR_CONTROL == 1
//	  current_percent = (__HAL_TIM_GET_COMPARE(&htim1, TIM_CHANNEL_1) - MAX_REVERSE)*100/PWM_RANGE;
//	  printf("\r\nCurrent Percent: %lu", current_percent);
/*	  scanf("%lu", &speed_percent);
	  //HAL_Delay(10000);
	  if (speed_percent != 0xffff && speed_percent <= 100 && speed_percent >= 0){
		  ccr = PWM_RANGE * speed_percent / 100 + MAX_REVERSE;
		  __HAL_TIM_SET_COMPARE(&htim1, TIM_CHANNEL_1, ccr);
	  }*/
	  while(osMessageQueueGetCount(sensor_data_mc_qHandle)){
	    	osMessageQueueGet(sensor_data_mc_qHandle, &sensor_data_mc, &helix_angle_prio, QUEUE_TIMEOUT);
	  }
	  scanf("%c", &lr_dir);
	  	  //HAL_Delay(10000);
	  	  if (lr_dir == ','){
	  		  ccr-=20;
	  		  __HAL_TIM_SET_COMPARE(&htim1, TIM_CHANNEL_1, ccr);
	  	  }
	  	  else if (lr_dir == '.'){
	  		  ccr+= 20;
	  		  __HAL_TIM_SET_COMPARE(&htim1, TIM_CHANNEL_1, ccr);

	  	  }
	  lr_dir = '\0';
	  speed_percent = 0xffff;
#elif MOTOR_CONTROL == 2

//	    while(osMessageQueueGetCount(pidconfig_queueHandle)){
//	    	osMessageQueueGet(pidconfig_queueHandle, &mode_pid_sp, &mode_pid_sp_prio, QUEUE_TIMEOUT);
//		    update_pidconfig(&mode_pid_sp);
//	    }
	  //Receive sensor data
	    while(osMessageQueueGetCount(sensor_data_mc_qHandle)){
	    	osMessageQueueGet(sensor_data_mc_qHandle, &sensor_data_mc, &helix_angle_prio, QUEUE_TIMEOUT);
	    }

	    //Update controller inputs
        Controller_P7_U.Omega_Primary = sensor_data_mc.prim_rpm; // ReadEngineSpeedSensor(); // e.g., 1500.0f
        Controller_P7_U.Omega_Secondary = sensor_data_mc.sec_rpm; // ReadSecondarySpeedSensor(); // e.g., 1500.0f

        //Remove helix angle offset
        helix_angle_offset_removed = sensor_data_mc.helix_angle - MIN_H_ANGLE;
        Controller_P7_U.Theta_Helix = helix_angle_offset_removed > 0 ? helix_angle_offset_removed : 0; //ReadGearRatioSensor(); // e.g., 1.5f

        // calculate speed command
        Controller_P7_step();

        //Convert output to PWM value
        motor_pwm_setpoint = scale_command(Controller_P7_Y.Command);

        //If engine off, limit speed of opening
        if (sensor_data_mc.prim_rpm <= 25.0 && motor_pwm_setpoint < NEUTRAL_SPEED - 1500){
        	motor_pwm_setpoint = NEUTRAL_SPEED - 1500;
        	flag_min_pos_safety = 1;
        	flag_max_pos_safety = 0;
        	flag_no_safety = 0;
        }
        //If engine off, prevent from closing at all
        else if (sensor_data_mc.prim_rpm <= 25.0 && motor_pwm_setpoint > NEUTRAL_SPEED){
        	motor_pwm_setpoint = NEUTRAL_SPEED;
        	flag_min_pos_safety = 0;
        	flag_max_pos_safety = 1;
        	flag_no_safety = 0;
        }
        //Software limit to limit how far helix can open
        if (sensor_data_mc.helix_angle >= MAX_H_ANGLE && motor_pwm_setpoint > NEUTRAL_SPEED){
        	motor_pwm_setpoint = NEUTRAL_SPEED;
        	flag_min_pos_safety = 0;
        	flag_max_pos_safety = 1;
        	flag_no_safety = 0;

        }
        else if (sensor_data_mc.helix_angle <= MIN_H_ANGLE && motor_pwm_setpoint < NEUTRAL_SPEED){
        	motor_pwm_setpoint = NEUTRAL_SPEED;
        	flag_min_pos_safety = 1;
        	flag_max_pos_safety = 0;
        	flag_no_safety = 0;
        }
        else{
        	flag_min_pos_safety = 0;
        	flag_max_pos_safety = 0;
        	flag_no_safety = 1;
        }

        //If motor enable button is not pressed, set motor speed to neutral
        if (HAL_GPIO_ReadPin(MC_Enable_GPIO_Port, MC_Enable_Pin) == GPIO_PIN_SET){
        	motor_pwm_setpoint = NEUTRAL_SPEED;
        }

        //Update PWM
        __HAL_TIM_SET_COMPARE(&htim1, TIM_CHANNEL_1, motor_pwm_setpoint);

        // Send filtered data to log
    	if(isLogging){
    		sensor_data_log.prim_rpm = Controller_P7_Y.Primary_Speed;
    		sensor_data_log.sec_rpm = Controller_P7_Y.Secondary_Speed;
    		osMessageQueuePut(sensor_data_log_qHandle, &sensor_data_log, 0, 0);
    	}

#else
	#error "invalid MOTOR_CONTROL value"
#endif
  }
  /* USER CODE END Start_Motor_Control */
}

void Start_Debug_Disp(void *argument)
{
  /* USER CODE BEGIN Start_Debug_Disp */
  /* Infinite loop */
#if DEBUG == 1

	float prim_rpm = 0;
	uint8_t prim_rpm_prio = 0;
	float sec_rpm = 0;
	uint8_t sec_rpm_prio = 0;
	float throttle_angle = 0;
	uint8_t throttle_angle_prio = 0;
	float helix_angle = 0;
	uint8_t helix_angle_prio = 0;
	const uint32_t QUEUE_TIMEOUT= 0;
	sensor_data_t sensor_data_debug = {0};
#endif

  for(;;)
  {

#if DEBUG == 0
    osDelay(1000);

#else DEBUG == 1
    osDelay(10);

//    BSP_LED_Toggle(LED_RED);

//    while(osMessageQueueGetCount(helix_angle_queueHandle)){
//    	osMessageQueueGet(helix_angle_queueHandle, &helix_angle, &helix_angle_prio, QUEUE_TIMEOUT);
//    }
//
//    while(osMessageQueueGetCount(throttle_angle_queueHandle)){
//    	osMessageQueueGet(throttle_angle_queueHandle, &throttle_angle, &throttle_angle_prio, QUEUE_TIMEOUT);
//    }
//
//    while(osMessageQueueGetCount(pri_rpm_queueHandle)){
//    	osMessageQueueGet(pri_rpm_queueHandle, &prim_rpm, &prim_rpm_prio, QUEUE_TIMEOUT);
//    }
//
//    while(osMessageQueueGetCount(sec_rpm_queueHandle)){
//    	osMessageQueueGet(sec_rpm_queueHandle, &sec_rpm, &sec_rpm_prio, QUEUE_TIMEOUT);
//    }
//    while(osMessageQueueGetCount(sensor_data_debug_qHandle)){
 //   	osMessageQueueGet(sensor_data_debug_qHandle, &sensor_data_debug, &helix_angle_prio, QUEUE_TIMEOUT);
//    }
#if MOTOR_CONTROL != 1

//    print_debug_sensor_vals(sensor_data_debug.prim_rpm, sensor_data_debug.sec_rpm, sensor_data_debug.throttle_angle, sensor_data_debug.helix_angle);\

    #endif
#endif
  }
  /* USER CODE END Start_Debug_Disp */
}

void receiveRFCommand(void *argument)
{
  /* USER CODE BEGIN receiveRFCommand */
  /* Infinite loop */
  const uint32_t QUEUE_TIMEOUT= 0;

#if DEBUG == 1
  uint32_t prev_rfrec_task_tick = __HAL_TIM_GET_COUNTER(&htim5);
  uint32_t curr_rfrec_task_tick = prev_rfrec_task_tick;
#endif

  for(;;)
  {

#if DEBUG == 1
	curr_rfrec_task_tick = __HAL_TIM_GET_COUNTER(&htim5);
	rfrec_task_loop_time = curr_rfrec_task_tick - prev_rfrec_task_tick;
	prev_rfrec_task_tick = curr_rfrec_task_tick;
#endif

	if(nrf_irq_flag){
		if (nrf24_data_available()){
			// Receive in command
			nrf24_receive(data_Rx, PLD_SIZE);
			osMessageQueuePut(RFCommandQueueHandle, data_Rx, 0, QUEUE_TIMEOUT);
			nrf24_flush_rx();
		}
	}
	if(uart_command_flag){
		uart_command_flag = 0;
		osMessageQueuePut(RFCommandQueueHandle, rx_uart3_buffer, 0, QUEUE_TIMEOUT);
		memset(rx_uart3_buffer,0, sizeof(rx_uart3_buffer));
	}
    osDelay(10);
  }
  /* USER CODE END receiveRFCommand */
}

void processRFCommand(void *argument)
{
  /* USER CODE BEGIN processRFCommand */
  /* Infinite loop */
  static char command[16];
#if DEBUG == 1
	uint32_t prev_proc_rf_task_tick = __HAL_TIM_GET_COUNTER(&htim5);
	uint32_t curr_proc_rf_task_tick = prev_proc_rf_task_tick;
#endif

  for(;;)
  {

#if DEBUG == 1
	  curr_proc_rf_task_tick = __HAL_TIM_GET_COUNTER(&htim5);
	  proc_rf_task_loop_time = curr_proc_rf_task_tick - prev_proc_rf_task_tick;
	prev_proc_rf_task_tick = curr_proc_rf_task_tick;
#endif

	if(osMessageQueueGet(RFCommandQueueHandle, command, NULL, 10) == osOK){
		if (strncmp((char*)command, "PID", 3) == 0){ // Change PID Values
			BSP_LED_Toggle(LED_GREEN);
			// Read in value to be changed (P1,I2,D4, Etc.)
			char rx_command[20];
			char code[3];
			float value = 0;
			int parsed, value_int;
			if((strncmp((char*)command, "PID SP1", 7) || strncmp((char*)command, "PID SP3", 7) == 0) == 0){
				parsed = sscanf((char*)command, "%s %3s %d", rx_command, code, &value_int);
				if(parsed == 3){ // Successful parsing of command
				  // Change the value in memory
				  CHANGE_PID(code,value_int);
				}
			} else{
				parsed = sscanf((char*)command, "%s %3s %f", rx_command, code, &value);
				if(parsed == 3){ // Successful parsing of command
				  // Change the value in memory
				  CHANGE_PID(code,value);
				}

			}
//		    PRINT_PID();

		  } else if(strncmp((char*)command, "DOWNLOAD_LOG",12) == 0){ // Download log file from SD card
			  BSP_LED_Toggle(LED_GREEN);
			  HAL_Delay(100);
//			  TRANSMIT_LOG();
			  TRANSMIT_LOG_USB();
		  } else if(strncmp((char*)command, "CHANGE_RATE", 11) == 0){ // Change the logging rate
			  BSP_LED_Toggle(LED_GREEN);
			  sscanf((char*)data_Rx, "%*s %d", &log_rate);
			  CHANGE_PID("LOG",0);
			  PRINT_PID();
		  } else if(strncmp((char*)command, "TEST_RF",7) == 0){ // Send a message back if in range
			  // Do nothing since auto_ack is enabled the result variable will determine if a transmission is successful or not
			  BSP_LED_Toggle(LED_GREEN);
		  }
	}
    osDelay(10);
  }
  /* USER CODE END processRFCommand */
}

void logData(void *argument)
{
  /* USER CODE BEGIN logData */
	sensor_data_t sensor_data_log = {0};
	uint8_t prio = 0;
	const uint32_t QUEUE_TIMEOUT = 0;
	uint32_t log_number = 0; //incoming data is most recent value at 1ms timesteps
	uint16_t log_rate = 1; //log timestep in ms
  /* Infinite loop */
#if DEBUG == 1
	uint32_t prev_log_task_tick = __HAL_TIM_GET_COUNTER(&htim5);
	uint32_t curr_log_task_tick = prev_log_task_tick;
#endif

  for(;;)
  {

#if DEBUG == 1
	  curr_log_task_tick = __HAL_TIM_GET_COUNTER(&htim5);
	  log_task_loop_time = curr_log_task_tick - prev_log_task_tick;
	  prev_log_task_tick = curr_log_task_tick;
#endif
	BSP_LED_Toggle(LED_RED);
	if (logSwitchflg){
		logSwitchflg = 0;
		if(HAL_GPIO_ReadPin(LOG_SW_GPIO_Port,LOG_SW_Pin) == GPIO_PIN_SET){
			isLogging = false;
			STOP_LOG(); // Close log file
		} else{
			isLogging = true;
			START_LOG(); // Open log file
		}
	}
	if(isLogging){

		while(osMessageQueueGetCount(sensor_data_log_qHandle)){
			osMessageQueueGet(sensor_data_log_qHandle, &sensor_data_log, &prio, QUEUE_TIMEOUT);

			//skips any sensor data that isn't a multiple of log rate
			if (log_number++ % log_rate){
				continue;
			}

			LOG_DATA_POINT(log_number, sensor_data_log.prim_rpm, sensor_data_log.sec_rpm); //TODO: Connect to actual parameters
		}
	}

	else{
		log_number = 0;
	}
    osDelay(30);
  }
  /* USER CODE END logData */
}

/* USER CODE BEGIN Application */
//float init_helix_offset(){
//	return 0
//}
/* USER CODE END Application */
